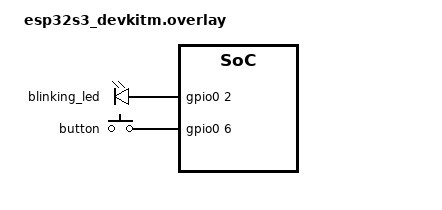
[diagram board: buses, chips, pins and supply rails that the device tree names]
/ {
    leds {
        compatible = "gpio-leds";
        blinking_led: blinking_led {
            gpios = <&gpio0 2 GPIO_ACTIVE_HIGH>;
        };
    };

    buttons {
        compatible = "gpio-keys";
        button: button {
            gpios = <&gpio0 6 GPIO_ACTIVE_HIGH>;
        };
    };
};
